# MCU_CPSW0_NUSS register map
Vendor: Texas Instruments
Registers are 32-bit, read-write, reset 0x0 unless marked. A register's access mark holds for its fields unless they carry their own. Offsets are as the file gives them; [hi:lo] are bit positions; lines under a group give offsets from that group; {n}, {i} and the like mark numbered series.

## MCU_CPSW0_NUSS (part 2 of 2)
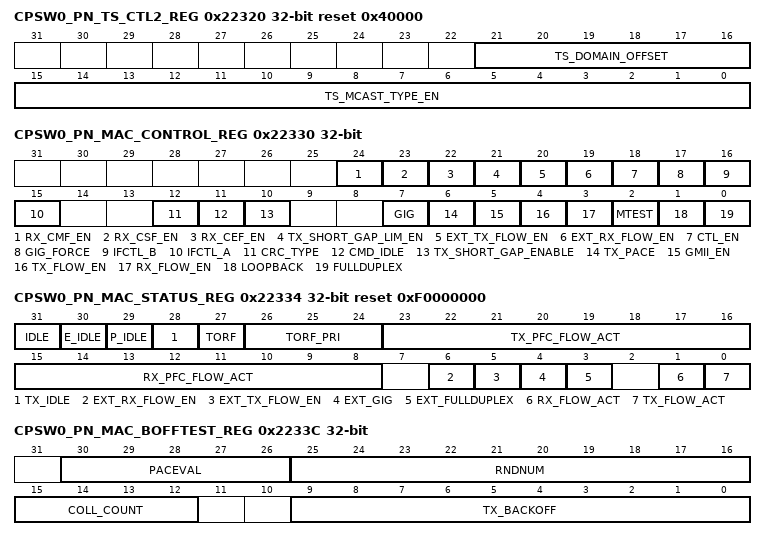
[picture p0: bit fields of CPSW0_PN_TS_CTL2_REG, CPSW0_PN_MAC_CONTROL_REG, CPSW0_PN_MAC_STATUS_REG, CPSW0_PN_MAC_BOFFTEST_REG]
0x22320 CPSW0_PN_TS_CTL2_REG reset 0x40000 — Enet Port N Time Sync Control 2
  [21:16] TS_DOMAIN_OFFSET — Time Sync Domain Offset
  [15:0] TS_MCAST_TYPE_EN — Time Sync Multicast Destination Address Type Enable
0x22330 CPSW0_PN_MAC_CONTROL_REG — Enet Port N Mac Control
  [24] RX_CMF_EN — RX Copy MAC Control Frames Enable
  [23] RX_CSF_EN — RX Copy Short Frames Enable
  [22] RX_CEF_EN — RX Copy Error Frames Enable
  [21] TX_SHORT_GAP_LIM_EN — Transmit Short Gap Limit Enable
  [20] EXT_TX_FLOW_EN — External Transmit Flow Control Enable
  [19] EXT_RX_FLOW_EN — External Receive Flow Control Enable
  [18] CTL_EN — Control Enable
  [17] GIG_FORCE — Gigabit Mode Force
  [16] IFCTL_B — Interface Control B
  [15] IFCTL_A — Interface Control A
  [12] CRC_TYPE — Port CRC Type
  [11] CMD_IDLE — Command Idle
  [10] TX_SHORT_GAP_ENABLE — Transmit Short Gap Enable
  [7] GIG — Gigabit Mode
  [6] TX_PACE — Transmit Pacing Enable
  [5] GMII_EN — GMII Enable
  [4] TX_FLOW_EN — Transmit Flow Control Enable
  [3] RX_FLOW_EN — Receive Flow Control Enable
  [2] MTEST — Manufacturing Test Mode
  [1] LOOPBACK — Loop Back Mode
  [0] FULLDUPLEX — Full Duplex mode
0x22334 CPSW0_PN_MAC_STATUS_REG ro reset 0xF0000000 — Enet Port N Mac Status
  [31] IDLE — cpxmac_sl IDLE
  [30] E_IDLE — cpxmac_sl IDLE
  [29] P_IDLE — cpxmac_sl IDLE
  [28] TX_IDLE — cpxmac_sl IDLE
  [27] TORF — Top of receive FIFO flowCPSW0_CONTROL trigger occurred. This bit is write one to clear.
  [26:24] TORF_PRI — The lowest priority that caused top of receive FIFO flowCPSW0_CONTROL trigger since the last write to clear. This field is write 0x7 to clear.
  [23:16] TX_PFC_FLOW_ACT — Transmit Priority Based Flow Control Active (priority 7 down to 0)
  [15:8] RX_PFC_FLOW_ACT — Receive Priority Based Flow Control Active (priority 7 down to 0)
  [6] EXT_RX_FLOW_EN — External Transmit Flow Control Enable
  [5] EXT_TX_FLOW_EN — External Receive Flow Control Enable
  [4] EXT_GIG — External GIG mode
  [3] EXT_FULLDUPLEX — External Fullduplex
  [1] RX_FLOW_ACT — Receive Flow Control Active
  [0] TX_FLOW_ACT — Transmit Flow Control Active
0x22338 CPSW0_PN_MAC_SOFT_RESET_REG — Enet Port N Mac Soft Reset
  [0] SOFT_RESET — Software reset
0x2233C CPSW0_PN_MAC_BOFFTEST_REG access per field — Enet Port N Mac Backoff Test
  [30:26] PACEVAL rw — Pacing Register Current Value
  [25:16] RNDNUM rw — Backoff Random Number Generator
  [15:12] COLL_COUNT ro — Collision Count
  [9:0] TX_BACKOFF ro — Backoff Count
0x22340 CPSW0_PN_MAC_RX_PAUSETIMER_REG — Enet Port N 802.3 Receive Pause Timer
  [15:0] RX_PAUSETIMER — RX Pause Timer Value
0x22350 CPSW0_PN_MAC_RXN_PAUSETIMER_REG_y — Enet Port N PFC Priority P Rx Pause Timer Offset = 00022350h + (y * 4h); where y = 0h to 7h
  [15:0] RX_PAUSETIMER — RX Pause Timer Value
0x22370 CPSW0_PN_MAC_TX_PAUSETIMER_REG — Enet Port N 802.3 Tx Pause Timer
  [15:0] TX_PAUSETIMER — TX Pause Timer Value
0x22380 CPSW0_PN_MAC_TXN_PAUSETIMER_REG_y — Enet Port N PFC Priority P Tx Pause Timer Offset = 00022380h + (y * 4h); where y = 0h to 7h
  [15:0] TX_PAUSETIMER — TX Pause Timer Value
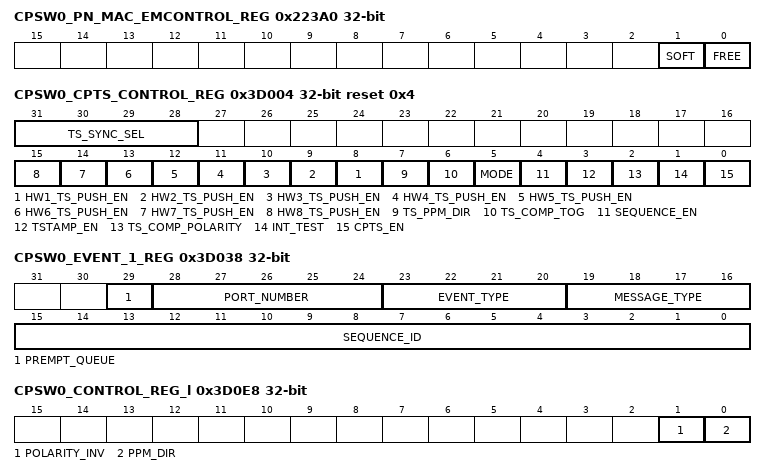
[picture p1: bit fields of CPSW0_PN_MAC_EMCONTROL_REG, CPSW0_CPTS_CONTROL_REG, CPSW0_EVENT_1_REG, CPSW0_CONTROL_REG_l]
0x223A0 CPSW0_PN_MAC_EMCONTROL_REG — Enet Port N Emulation Control
  [1] SOFT — Emulation Soft Bit
  [0] FREE — Emulation Free Bit
0x223A4 CPSW0_PN_MAC_TX_GAP_REG reset 0xC — Enet Port N Tx Inter Packet Gap
  [15:0] TX_GAP — Transmit Inter-Packet Gap
0x32000 CPSW0_FETCH_LOC_y — These are the RAM locations for one ethernet port Offset = 00032000h + (y * 4h); where y = 0h to 7Fh
  [21:0] LOC — RAM Location
0x3A200 CPSW0_RXGOODFRAMES — Total number of good frames received
  [31:0] COUNT
0x3A204 CPSW0_RXBROADCASTFRAMES — Total number of good broadcast frames received
  [31:0] COUNT
0x3A208 CPSW0_RXMULTICASTFRAMES — Total number of good multicast frames received
  [31:0] COUNT
0x3A20C CPSW0_RXPAUSEFRAMES — Total number of pause frames received
  [31:0] COUNT
0x3A210 CPSW0_RXCRCERRORS — Total number of CRC errors frames received
  [31:0] COUNT
0x3A214 CPSW0_RXALIGNCODEERRORS — Total number of alignment/code errors received
  [31:0] COUNT
0x3A218 CPSW0_RXOVERSIZEDFRAMES — Total number of oversized frames received
  [31:0] COUNT
0x3A21C CPSW0_RXJABBERFRAMES — Total number of jabber frames received
  [31:0] COUNT
0x3A220 CPSW0_RXUNDERSIZEDFRAMES — Total number of undersized frames received
  [31:0] COUNT
0x3A224 CPSW0_RXFRAGMENTS — Total number of fragmented frames received
  [31:0] COUNT
0x3A228 CPSW0_ALE_DROP — Total number of frames dropped by the ALE
  [31:0] COUNT
0x3A22C CPSW0_ALE_OVERRUN_DROP — Total number of overrun frames dropped by the ALE
  [31:0] COUNT
0x3A230 CPSW0_RXOCTETS — Total number of received bytes in good frames
  [31:0] COUNT
0x3A234 CPSW0_TXGOODFRAMES — Total number of good frames transmitted
  [31:0] COUNT
0x3A238 CPSW0_TXBROADCASTFRAMES — Total number of good broadcast frames transmitted
  [31:0] COUNT
0x3A23C CPSW0_TXMULTICASTFRAMES — Total number of good multicast frames transmitted
  [31:0] COUNT
0x3A240 CPSW0_TXPAUSEFRAMES — Total number of pause frames transmitted
  [31:0] COUNT
0x3A244 CPSW0_TXDEFERREDFRAMES — Total number of deferred frames transmitted
  [31:0] COUNT
0x3A248 CPSW0_TXCOLLISIONFRAMES — Total number of transmitted frames experiencing a collision
  [31:0] COUNT
0x3A24C CPSW0_TXSINGLECOLLFRAMES — Total number of transmitted frames experiencing a single collision
  [31:0] COUNT
0x3A250 CPSW0_TXMULTCOLLFRAMES — Total number of transmitted frames experiencing multiple collisions
  [31:0] COUNT
0x3A254 CPSW0_TXEXCESSIVECOLLISIONS — Total number of transmitted frames abandoned due to excessive collisions
  [31:0] COUNT
0x3A258 CPSW0_TXLATECOLLISIONS — Total number of transmitted frames abandoned due to a late collision
  [31:0] COUNT
0x3A25C CPSW0_RXIPGERROR — Total number of receive inter-packet gap errors (10G only)
  [31:0] COUNT
0x3A260 CPSW0_TXCARRIERSENSEERRORS — Total number of transmitted frames that experienced a carrier loss
  [31:0] COUNT
0x3A264 CPSW0_TXOCTETS — Total number of bytes in all good frames transmitted
  [31:0] COUNT
0x3A268 CPSW0_OCTETFRAMES64 — Total number of 64-byte frames received and transmitted
  [31:0] COUNT
0x3A26C CPSW0_OCTETFRAMES65T127 — Total number of frames of size 65 to 127 bytes received and transmitted
  [31:0] COUNT
0x3A270 CPSW0_OCTETFRAMES128T255 — Total number of frames of size 128 to 255 bytes received and transmitted
  [31:0] COUNT
0x3A274 CPSW0_OCTETFRAMES256T511 — Total number of frames of size 256 to 511 bytes received and transmitted
  [31:0] COUNT
0x3A278 CPSW0_OCTETFRAMES512T1023 — Total number of frames of size 512 to 1023 bytes received and transmitted
  [31:0] COUNT
0x3A27C CPSW0_OCTETFRAMES1024TUP — Total number of frames of size 1024 to rx_maxlen bytes received and 1024 bytes or greater transmitted
  [31:0] COUNT
0x3A280 CPSW0_NETOCTETS — Total number of bytes received and transmitted
  [31:0] COUNT
0x3A284 CPSW0_RX_BOTTOM_OF_FIFO_DROP — Receive Bottom of FIFO Drop
  [31:0] COUNT
0x3A288 CPSW0_PORTMASK_DROP — Total number of dropped frames received due to portmask
  [31:0] COUNT
0x3A28C CPSW0_RX_TOP_OF_FIFO_DROP — Receive Top of FIFO Drop
  [31:0] COUNT
0x3A290 CPSW0_ALE_RATE_LIMIT_DROP — Total number of dropped frames due to ALE Rate Limiting
  [31:0] COUNT
0x3A294 CPSW0_ALE_VID_INGRESS_DROP — Total number of dropped frames due to ALE VID Ingress
  [31:0] COUNT
0x3A298 CPSW0_ALE_DA_EQ_SA_DROP — Total number of dropped frames due to DA=SA
  [31:0] COUNT
0x3A29C CPSW0_ALE_BLOCK_DROP — Total number of dropped frames due to ALE Block Mode
  [31:0] COUNT
0x3A2A0 CPSW0_ALE_SECURE_DROP — Total number of dropped frames due to ALE Secure Mode
  [31:0] COUNT
0x3A2A4 CPSW0_ALE_AUTH_DROP — Total number of dropped frames due to ALE Authentication
  [31:0] COUNT
0x3A2A8 CPSW0_ALE_UNKN_UNI — ALE Receive Unknown Unicast
  [31:0] COUNT
0x3A2AC CPSW0_ALE_UNKN_UNI_BCNT — ALE Receive Unknown Unicast Bytecount
  [31:0] COUNT
0x3A2B0 CPSW0_ALE_UNKN_MLT — ALE Receive Unknown Multicast
  [31:0] COUNT
0x3A2B4 CPSW0_ALE_UNKN_MLT_BCNT — ALE Receive Unknown Multicast Bytecount
  [31:0] COUNT
0x3A2B8 CPSW0_ALE_UNKN_BRD — ALE Receive Unknown Broadcast
  [31:0] COUNT
0x3A2BC CPSW0_ALE_UNKN_BRD_BCNT — ALE Receive Unknown Broadcast Bytecount
  [31:0] COUNT
0x3A2C0 CPSW0_ALE_POL_MATCH — ALE Policer Matched
  [31:0] COUNT
0x3A2C4 CPSW0_ALE_POL_MATCH_RED — ALE Policer Matched and Condition Red
  [31:0] COUNT
0x3A2C8 CPSW0_ALE_POL_MATCH_YELLOW — ALE Policer Matched and Condition Yellow
  [31:0] COUNT
0x3A37C CPSW0_TX_MEMORY_PROTECT_ERROR — Transmit Memory Protect CRC Error
  [7:0] COUNT
0x3A380 CPSW0_ENET_PN_TX_PRI_REG_y — ENET Port n PRIORITY N Packet Count Offset = 0003A380h + (y * 4h); where y = 0h to 7h
  [31:0] PN_TX_PRIN
0x3A3A0 CPSW0_ENET_PN_TX_PRI_BCNT_REG_y — ENET Port n PRIORITY N Packet Byte Count Offset = 0003A3A0h + (y * 4h); where y = 0h to 7h
  [31:0] PN_TX_PRIN_BCNT — ENET Port n PRIORITY N Packet Byte Count
0x3A3C0 CPSW0_ENET_PN_TX_PRI_DROP_REG_y — ENET Port n PRIORITY N Packet Drop Count Offset = 0003A3C0h + (y * 4h); where y = 0h to 7h
  [31:0] PN_TX_PRIN_DROP — ENET Port n PRIORITY N Packet Drop Count
0x3A3E0 CPSW0_ENET_PN_TX_PRI_DROP_BCNT_REG_y — ENET Port n PRIORITY N Packet Drop Byte Count Offset = 0003A3E0h + (y * 4h); where y = 0h to 7h
  [31:0] PN_TX_PRIN_DROP_BCNT — ENET Port n PRIORITY N Packet Drop Byte Count
0x3D004 CPSW0_CPTS_CONTROL_REG reset 0x4 — Time Sync Control Register
  [31:28] TS_SYNC_SEL — TS_SYNC output timestamp counter bit select
  [n+7] HW{n}_TS_PUSH_EN (n=1..8) — Hardware push {n} enable
  [7] TS_PPM_DIR — Timestamp PPM Direction
  [6] TS_COMP_TOG — Timestamp Compare Toggle mode: 0=TS_COMP is in non-toggle mode, 1=TS_COMP is in toggle mode
  [5] MODE — Timestamp mode
  [4] SEQUENCE_EN — Sequence Enable
  [3] TSTAMP_EN — Host Receive Timestamp Enable
  [2] TS_COMP_POLARITY
  [1] INT_TEST — Interrupt test
  [0] CPTS_EN — Time sync enable
0x3D008 CPSW0_RFTCLK_SEL_REG — Added RFTCLK_SEL Register Bit Field Description RFTCLK Select Register
  [4:0] RFTCLK_SEL — Reference clock select. This bit field is used to control an external multiplexer that selects one out of 8 clocks for time sync reference. 0h: Selects CPSWHSDIV_CLKOUT2 clock 1h: Selects MAINHSDIV_CLKOUT3 clock 2h: Selects MCU_CPTS0_RFT_CLK I/O pin 3h: Selects CPTS0_RFT_CLK I/O pin 4h: Selects MCU_EXT_REFCLK0 I/O pin 5h: Selects EXT_REFCLK1 I/O pin 6h: Selects PCIE0_TXI0_CLK clock 7h: Selects PCIE1_TXI0_CLK clock The RFTCLK_SEL value can be written only when the [0] CPTS_EN and [3] TSTAMP_EN bits are cleared to zero in the
0x3D00C CPSW0_TS_PUSH_REG wo — Time Stamp Event Push Register
  [0] TS_PUSH — Time stamp event push
0x3D010 CPSW0_TS_LOAD_VAL_REG — Time Stamp Load Low Value Register
  [31:0] TS_LOAD_VAL — Time stamp load low value
0x3D014 CPSW0_TS_LOAD_EN_REG wo — Time Stamp Load Enable Register
  [0] TS_LOAD_EN — Time stamp load enable
0x3D018 CPSW0_TS_COMP_VAL_REG — Time Stamp Comparison Low Value Register
  [31:0] TS_COMP_VAL — Time stamp comparison low value
0x3D01C CPSW0_TS_COMP_LEN_REG — Time Stamp Comparison Length Register
  [31:0] TS_COMP_LENGTH — Time stamp comparison length
0x3D020 CPSW0_INTSTAT_RAW_REG — Interrupt Status Register Raw
  [0] TS_PEND_RAW — TS_PEND_RAW int read (before enable)
0x3D024 CPSW0_INTSTAT_MASKED_REG ro — Interrupt Status Register Masked
  [0] TS_PEND — TS_PEND masked interrupt read (after enable)
0x3D028 CPSW0_INT_ENABLE_REG — Interrupt Enable Register
  [0] TS_PEND_EN — TS_PEND masked interrupt enable
0x3D02C CPSW0_TS_COMP_NUDGE_REG — Time Stamp Comparison Nudge Register
  [7:0] NUDGE — This 2s complement number is added to the ts_comp_length value to increase or decrease the TS_COMP length by the nudge amount
0x3D030 CPSW0_EVENT_POP_REG wo — Event Pop Register
  [0] EVENT_POP
0x3D034 CPSW0_EVENT_0_REG ro — Event 0 Register
  [31:0] TIME_STAMP
0x3D038 CPSW0_EVENT_1_REG ro — Event 1 Register
  [29] PREMPT_QUEUE, [28:24] PORT_NUMBER, [23:20] EVENT_TYPE, [19:16] MESSAGE_TYPE, [15:0] SEQUENCE_ID
0x3D03C CPSW0_EVENT_2_REG ro — Event 2 Register
  [7:0] DOMAIN
0x3D040 CPSW0_EVENT_3_REG ro — Event 3 Register
  [31:0] TIME_STAMP
0x3D044 CPSW0_TS_LOAD_HIGH_VAL_REG — Time Stamp Load High Value Register
  [31:0] TS_LOAD_VAL — Time stamp load high value
0x3D048 CPSW0_TS_COMP_HIGH_VAL_REG — Time Stamp Comparison High Value Register
  [31:0] TS_COMP_HIGH_VAL — Time stamp comparison high value
0x3D04C CPSW0_TS_ADD_VAL_REG — TS Add Value Register
  [2:0] ADD_VAL — Add Value
0x3D050 CPSW0_TS_PPM_LOW_VAL_REG — Time Stamp PPM Low Value Register
  [31:0] TS_PPM_LOW_VAL — Time stamp PPM Low value
0x3D054 CPSW0_TS_PPM_HIGH_VAL_REG — Time Stamp PPM High Value Register
  [9:0] TS_PPM_HIGH_VAL — Time stamp PPM High value
0x3D058 CPSW0_TS_NUDGE_VAL_REG — Time Stamp Nudge Value Register
  [7:0] TS_NUDGE_VAL — Time stamp Nudge value
0x3D0E0 CPSW0_COMP_LOW_REG_l — Time Stamp Generate Function Comparison Low Value Offset = 0003D0E0h + (l * 20h); where l = 0h to 1h
  [31:0] COMP_LOW — Time Stamp Generate Function Comparison Low Value
0x3D0E4 CPSW0_COMP_HIGH_REG_l — Time Stamp Generate Function Comparison high Value Offset = 0003D0E4h + (l * 20h); where l = 0h to 1h
  [31:0] COMP_HIGH — Time Stamp Generate Function Comparison High Value
0x3D0E8 CPSW0_CONTROL_REG_l — Time Stamp Generate Function Control Offset = 0003D0E8h + (l * 20h); where l = 0h to 1h
  [1] POLARITY_INV — Time Stamp Generate Function Polarity Invert
  [0] PPM_DIR — Time Stamp Generate Function PPM Direction
0x3D0EC CPSW0_LENGTH_REG_l — Time Stamp Generate Function Length Value Offset = 0003D0ECh + (l * 20h); where l = 0h to 1h
  [31:0] LENGTH — Time Stamp Generate Function Length Value
0x3D0F0 CPSW0_PPM_LOW_REG_L — Time Stamp Generate Function PPM Low Value Offset = 0003D0F0h + (l * 20h); where l = 0h to 1h
  [31:0] PPM_LOW — Time Stamp Generate Function PPM Low Value
0x3D0F4 CPSW0_PPM_HIGH_REG_l — Time Stamp Generate Function PPM High Value Offset = 0003D0F4h + (l * 20h); where l = 0h to 1h
  [9:0] PPM_HIGH — Time Stamp Generate Function PPM High Value
0x3D0F8 CPSW0_NUDGE_REG_l — Time Stamp Generate Function Nudge Value Offset = 0003D0F8h + (l * 20h); where l = 0h to 1h
  [7:0] NUDGE — Time Stamp Generate Function Nudge Value
0x3D200 CPSW0_COMP_LOW_REG — Time Stamp ESTF Generate Function Comparison Low Value
  [31:0] COMP_LOW
0x3D204 CPSW0_COMP_HIGH_REG — Time Stamp ESTF Generate Function Comparison high Value
  [31:0] COMP_HIGH — Time Stamp ESTF Generate Function Comparison High Value
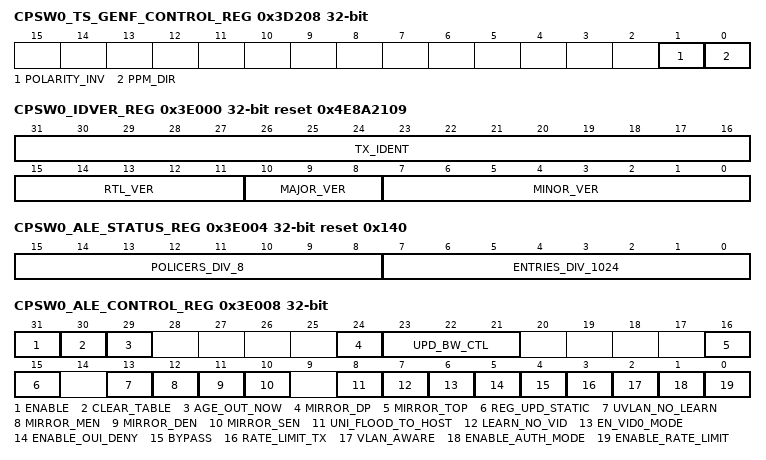
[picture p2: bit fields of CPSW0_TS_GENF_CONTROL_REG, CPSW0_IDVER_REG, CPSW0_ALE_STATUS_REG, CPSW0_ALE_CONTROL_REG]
0x3D208 CPSW0_TS_GENF_CONTROL_REG — Time Stamp ESTF Generate Function Control
  [1] POLARITY_INV — Time Stamp ESTF Generate Function Polarity Invert
  [0] PPM_DIR — Time Stamp ESTF Generate Function PPM Direction
0x3D20C CPSW0_LENGTH_REG — Time Stamp ESTF Generate Function Length Value
  [31:0] LENGTH
0x3D210 CPSW0_PPM_LOW_REG — Time Stamp ESTF Generate Function PPM Low Value
  [31:0] PPM_LOW
0x3D214 CPSW0_PPM_HIGH_REG — Time Stamp ESTF Generate Function PPM High Value
  [9:0] PPM_HIGH
0x3D218 CPSW0_NUDGE_REG — Time Stamp ESTF Generate Function Nudge Value
  [7:0] NUDGE
0x3E000 CPSW0_IDVER_REG ro reset 0x4E8A2109 — Identification and Version Register
  [31:16] TX_IDENT — Identification value
  [15:11] RTL_VER — RTL version value
  [10:8] MAJOR_VER — Major version value
  [7:0] MINOR_VER — Minor version value
0x3E004 CPSW0_ALE_STATUS_REG ro reset 0x140 — Status
  [15:8] POLICERS_DIV_8 — The number of policing entries divided by 8
  [7:0] ENTRIES_DIV_1024 — The number of ALE entries in the ALE table divided by 1024
0x3E008 CPSW0_ALE_CONTROL_REG — Control
  [31] ENABLE — Enable ALE
  [30] CLEAR_TABLE — Clear ALE Address table
  [29] AGE_OUT_NOW — Age Out Address Table Now
  [24] MIRROR_DP — This field defines the port to which traffic destined will be duplicated to
  [23:21] UPD_BW_CTL — The upd_bw_ctrl field allows for up to 8 times the rate in which adds, updates, touches, writes, and aging updates can occur
  [16] MIRROR_TOP — This field defines the destination port for the mirror traffic
  [15] REG_UPD_STATIC — Reg Update Static
  [13] UVLAN_NO_LEARN — Unknown VLAN No Learn
  [12] MIRROR_MEN — Mirror Match Entry Enable
  [11] MIRROR_DEN — Mirror Destination Port Enable
  [10] MIRROR_SEN — Mirror Source Port Enable
  [8] UNI_FLOOD_TO_HOST — Enable Port 0 Unicast Flood
  [7] LEARN_NO_VID
  [6] EN_VID0_MODE — Enable VLAN ID = 0 Mode
  [5] ENABLE_OUI_DENY — Enable OUI Deny Mode
  [4] BYPASS — ALE Bypass
  [3] RATE_LIMIT_TX — Rate Limit Transmit Mode
  [2] VLAN_AWARE — ALE VLAN Aware
  [1] ENABLE_AUTH_MODE — Enable MAC Authorization Mode
  [0] ENABLE_RATE_LIMIT — Enable Broadcast and Multicast Rate Limit
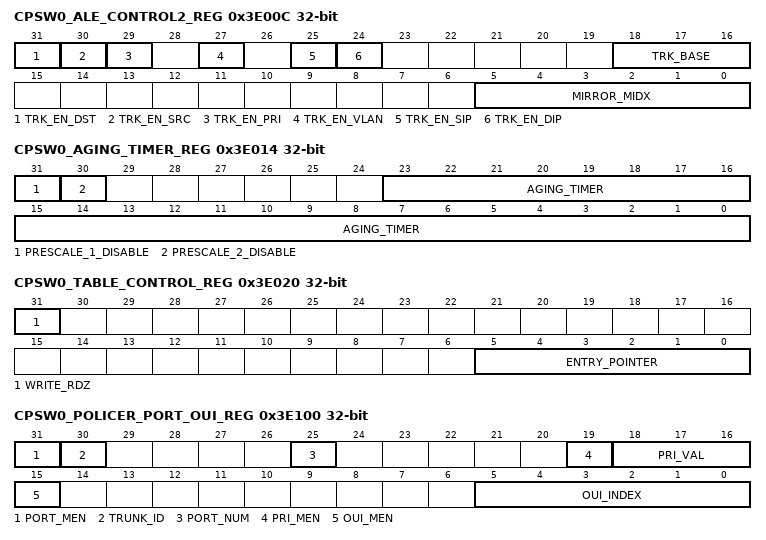
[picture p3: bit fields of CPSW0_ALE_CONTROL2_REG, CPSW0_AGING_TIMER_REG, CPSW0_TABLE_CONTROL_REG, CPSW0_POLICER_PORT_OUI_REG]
0x3E00C CPSW0_ALE_CONTROL2_REG — Control 2
  [31] TRK_EN_DST — Trunk Destination Enable
  [30] TRK_EN_SRC — Trunk Source Enable
  [29] TRK_EN_PRI — Trunk Priority Enable
  [27] TRK_EN_VLAN — Trunk VLAN Enable
  [25] TRK_EN_SIP — Trunk Source IP Address Enable
  [24] TRK_EN_DIP — Trunk Destination IP Address Enable
  [18:16] TRK_BASE — Trunk Base
  [5:0] MIRROR_MIDX — Mirror Match Index
0x3E010 CPSW0_PRESCALE_REG — Prescale
  [19:0] PRESCALE — ALE Prescale Register
0x3E014 CPSW0_AGING_TIMER_REG — Aging Timer
  [31] PRESCALE_1_DISABLE — ALE Prescaler 1 Disable: When set, removes 1,000 from the auto aging multiplier.
  [30] PRESCALE_2_DISABLE — ALE Prescaler 2 Disable: When set, removes 1,000 from the auto aging multiplier.
  [23:0] AGING_TIMER — ALE Aging Timer: When non-zero, auto-aging is enabled.
0x3E020 CPSW0_TABLE_CONTROL_REG — Table Control
  [31] WRITE_RDZ — Write Bit
  [5:0] ENTRY_POINTER — Table Entry Pointer
0x3E034 CPSW0_TABLE_WORD2_REG — Table Word 2
  [6:0] ENTRY_71_64 — Table Entry Bits 70:64
0x3E038 CPSW0_TABLE_WORD1_REG — Table Word 1
  [31:0] ENTRY_63_32 — Table Entry Bits 63:32
0x3E03C CPSW0_TABLE_WORD0_REG — Table Word 0
  [31:0] ENTRY_31_0 — Table Entry Bits 31:0
0x3E090 CPSW0_UNKNOWN_VLAN_REG — Unknown VLAN Member List
  [1:0] LIST
0x3E094 CPSW0_UNKNOWN_MCAST_FLOOD_REG — Unknown VLAN Multicast Flood Mask
  [1:0] MASK
0x3E098 CPSW0_UNKNOWN_REG_MCAST_FLOOD_REG — Unknown VLAN Multicast Flood Mask
  [1:0] MASK — Unknown VLAN Registered Multicast Flood Mask
0x3E09C CPSW0_FORCE_UNTAGGED_EGRESS_REG — Unknown VLAN Force Untagged Egress
  [1:0] MASK — Force Untagged Egress Mask
0x3E0C0 CPSW0_VLAN_MASK_MUX0_REG ro reset 0x3 — VLAN Mask Mux 0 Select
  [1:0] MASK — Force Untagged Egress Mask
{0x3E0C0+4i} CPSW0_VLAN_MASK_MUX{i}_REG (i=1..7) — VLAN Mask Mux {i} Select
  [1:0] MASK — Force Untagged Egress Mask
0x3E100 CPSW0_POLICER_PORT_OUI_REG — Specifies the port, frame priority, and OUI address index as well as match enables for port, frame priority, and OUI address matching
  [31] PORT_MEN — Enabled port match for the selected policing/classifier entry
  [30] TRUNK_ID — When set indicates the port number is a trunk group
  [25] PORT_NUM — If enabled, specifies the port address to match for the selected policing/classifier entry
  [19] PRI_MEN — Enabled frame priority match for the selected policing/classifier entry
  [18:16] PRI_VAL — If enabled, specifies the frame priority to match for the selected policing/classifier entry
  [15] OUI_MEN — Enabled frame OUI address match for the selected policing/classifier entry
  [5:0] OUI_INDEX — If enabled, specifies the ALE OUI address lookup table index to match for the selected policing/classifier entry
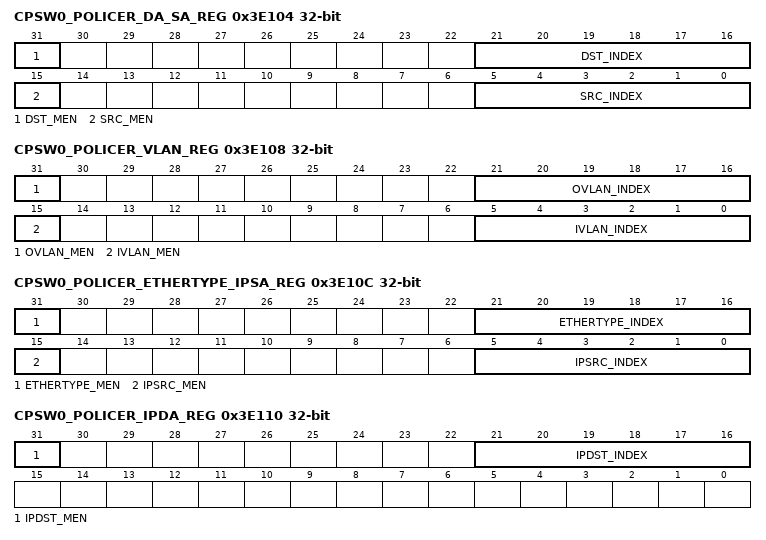
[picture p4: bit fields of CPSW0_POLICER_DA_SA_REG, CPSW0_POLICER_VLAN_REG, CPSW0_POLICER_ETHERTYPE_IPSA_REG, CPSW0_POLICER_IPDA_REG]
0x3E104 CPSW0_POLICER_DA_SA_REG — Specifies the match enable/match index for the L2 destination and L2 source addresses
  [31] DST_MEN — Enabled frame L2 destination address match for the selected policing/classifier entry
  [21:16] DST_INDEX — If enabled, specifies the ALE L2 destination address lookup table index to match for the selected policing/classifier entry
  [15] SRC_MEN — Enabled frame L2 source address match for the selected policing/classifier entry
  [5:0] SRC_INDEX — If enabled, specifies the ALE L2 source address lookup table index to match for the selected policing/classifier entry
0x3E108 CPSW0_POLICER_VLAN_REG — Specifies the match enable/match index for the Outer VLAN and Inner VLAN addresses
  [31] OVLAN_MEN — Enabled frame Outer VLAN address match for the selected policing/classifier entry
  [21:16] OVLAN_INDEX — If enabled, specifies the ALE Outer VLAN address lookup table index to match for the selected policing/classifier entry
  [15] IVLAN_MEN — Enabled frame Inner VLAN address match for the selected policing/classifier entry
  [5:0] IVLAN_INDEX — If enabled, specifies the ALE Inner VLAN address lookup table index to match for the selected policing/classifier entry
0x3E10C CPSW0_POLICER_ETHERTYPE_IPSA_REG — Specifies the match enable/match index for the Ether Type and IP Source address
  [31] ETHERTYPE_MEN — Enabled frame Ether Type match for the selected policing/classifier entry
  [21:16] ETHERTYPE_INDEX — If enabled, specifies the ALE Ether Type lookup table index to match for the selected policing/classifier entry
  [15] IPSRC_MEN — Enabled frame IP Source address match for the selected policing/classifier entry
  [5:0] IPSRC_INDEX — If enabled, specifies the ALE IP Source address lookup table index to match for the selected policing/classifier entry
0x3E110 CPSW0_POLICER_IPDA_REG — Specifies the match enable/match index for the IP Destination address
  [31] IPDST_MEN — Enabled frame IP Destination address match for the selected policing/classifier entry
  [21:16] IPDST_INDEX — If enabled, specifies the ALE IP Destination address lookup table index to match for the selected policing/classifier entry
0x3E118 CPSW0_POLICER_PIR_REG — Specifies the PIR idle increment value
  [31:0] PRI_IDLE_INC_VAL — The number added to the PIR counter every clock cycle. If 0, the PIR counter is disabled and packets will never be marked or processed as RED.
0x3E11C CPSW0_POLICER_CIR_REG — Specifies the CIR idle increment value
  [31:0] CIR_IDLE_INC_VAL — The number added to the CIR counter every clock cycle. If 0, the CIR counter is disabled.
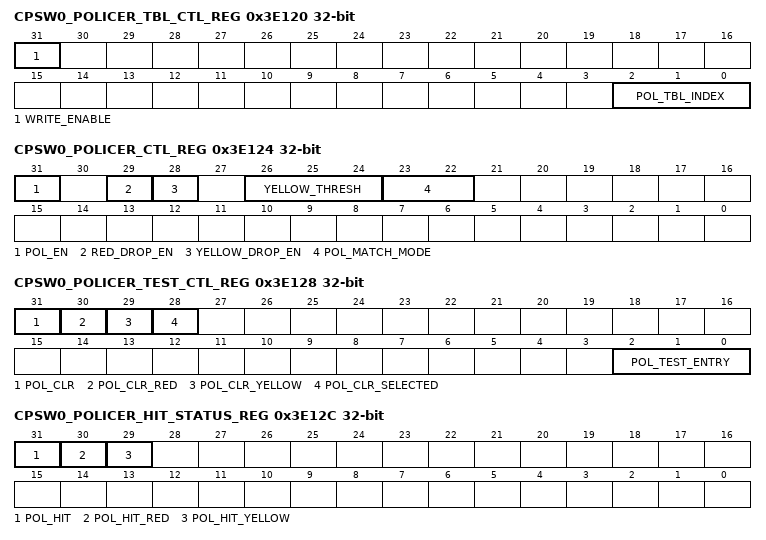
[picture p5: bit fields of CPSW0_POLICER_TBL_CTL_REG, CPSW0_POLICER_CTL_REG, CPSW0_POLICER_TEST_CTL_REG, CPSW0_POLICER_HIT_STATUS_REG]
0x3E120 CPSW0_POLICER_TBL_CTL_REG — The Policing Table Control is used to read or write the selected policing/classifier entry
  [31] WRITE_ENABLE — Setting this bit will write the POLICER_CFG 0-7 to the pol_tbl_index selected policing/classifier entry
  [2:0] POL_TBL_INDEX — This field specifies the policing/classifier entry to be read or written
0x3E124 CPSW0_POLICER_CTL_REG — The Control Enables color marking as well as internal ALE packet dropping
  [31] POL_EN — Enables the policing to color the packets. This also enables red or yellow drop capabilities.
  [29] RED_DROP_EN — Red Drop Enable
  [28] YELLOW_DROP_EN — Yellow Drop Enable
  [26:24] YELLOW_THRESH — Yellow Drop Threshold
  [23:22] POL_MATCH_MODE — Policing Match Mode determines what happens to packets that fail to hit any policing/classifier entry
0x3E128 CPSW0_POLICER_TEST_CTL_REG — The Policing Test Control enables the ability to determine which policing entry has been hit and whether they reported a red or yellow rate condition
  [31] POL_CLR — Policer Clear - This bit clears all the policer/classifier hit bits (policer_hit, policer_hit_red, and policer_hit_yellow bits for all policer/classifiers)
  [30] POL_CLR_RED — Policer Clear RED - This bit clears all policer/classifier RED hit bits (policer_hit_red for all policer/classifiers)
  [29] POL_CLR_YELLOW — Policer Clear YELLOW - This bit clears all policer/classifier YELLOW hit bits (policer_hit_yellow for all policer/classifiers)
  [28] POL_CLR_SELECTED — Policer Clear Selected - This bit clears the selected policer/classifier policer_hit, policer_hit_red, and policer_hit_yellow bits
  [2:0] POL_TEST_ENTRY — Policer Test Entry Pointer - This field selects the policer/classifier entry that will have hit bits read or written
0x3E12C CPSW0_POLICER_HIT_STATUS_REG ro — The policing hit status is a read only register that reads the hit bits of the selected policing/classifier
  [31] POL_HIT — This indicates that the selected policing/classifier via the pol_test_index field has been hit by a packet seen on any port that matches the policing/classifier entry match.
  [30] POL_HIT_RED — This indicates that the selected policing/classifier via the pol_test_index field has been hit during a RED condition by a packet seen on any port that matches the policing/classifier entry match.
  [29] POL_HIT_YELLOW — This indicates that the selected policing/classifier via the pol_test_index field has been hit during a YELLOW condition by a packet seen on any port that matches the policing/classifier entry match.
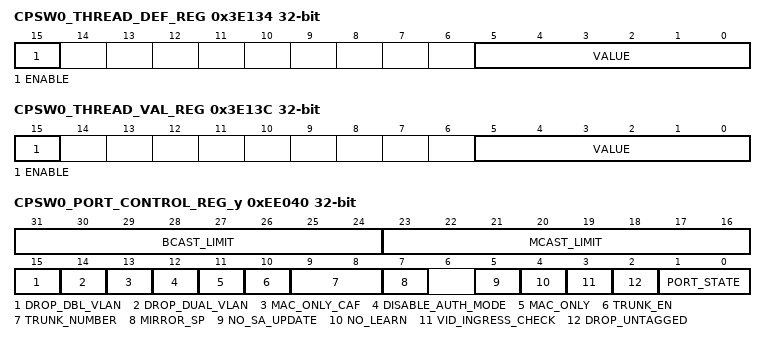
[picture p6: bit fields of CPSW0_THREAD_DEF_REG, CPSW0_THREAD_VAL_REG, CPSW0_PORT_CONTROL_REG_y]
0x3E134 CPSW0_THREAD_DEF_REG — The THREAD Mapping Default Value register is used to set the default thread ID when no classifier is matched
  [15] ENABLE — This field is the read or written enable for the Default Thread ID. When set, the switch will use the def_thread_val for the default thread ID if no classifier is matched. If clear, the switch will generate its own thread ID based on port and priority if there is no classifier match.
  [5:0] VALUE — This field is the read or written default thread ID value that is used for host traffic.
0x3E138 CPSW0_THREAD_CTL_REG — The THREAD Mapping Control register allows the highest matched classifier to return a particular thread ID for traffic sent to the host
  [2:0] ENTRY_PTR — Policer Thread Entry Pointer.
0x3E13C CPSW0_THREAD_VAL_REG — The THREAD Mapping Value register is used to set the thread ID for a particular classifier entry
  [15] ENABLE — This field is the read or written enable for the Thread ID. When set, the switch will use the thread_val for the particular classifier match. If clear, the switch will generate its own thread ID based on port and priority.
  [5:0] VALUE — This field is the read or written thread ID value that is used to map a classifier hit to thread ID for host traffic.
0xEE040 CPSW0_PORT_CONTROL_REG_y — Port N Control Offset = 0003E040h + (y * 4h); where y = 0h to 1h
  [31:24] BCAST_LIMIT — Broadcast Packet Rate Limit
  [23:16] MCAST_LIMIT — Multicast Packet Rate Limit
  [15] DROP_DBL_VLAN — DROP Double VLAN
  [14] DROP_DUAL_VLAN
  [13] MAC_ONLY_CAF — MAC Only Copy All Frames
  [12] DISABLE_AUTH_MODE — Disable MAC Authorization Mode
  [11] MAC_ONLY — MAC Only Mode
  [10] TRUNK_EN — Trunk Enable
  [9:8] TRUNK_NUMBER
  [7] MIRROR_SP — Mirror Source Port Enable
  [5] NO_SA_UPDATE — No Source Address Update
  [4] NO_LEARN — No Learn Mode
  [3] VID_INGRESS_CHECK — VLAN ID Ingress Check
  [2] DROP_UNTAGGED — Drop Untagged Packets
  [1:0] PORT_STATE
